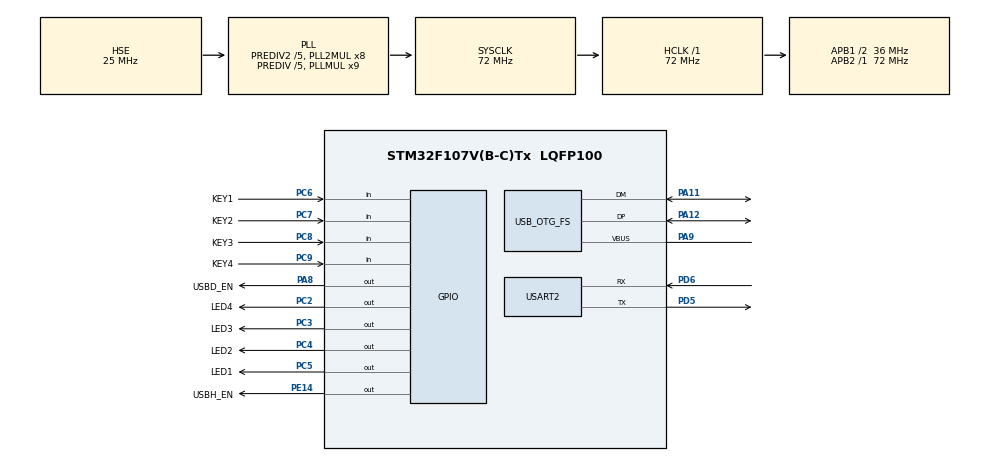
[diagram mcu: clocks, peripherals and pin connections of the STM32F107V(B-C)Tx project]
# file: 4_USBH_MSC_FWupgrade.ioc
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FATFS._MAX_LFN=100
FATFS._USE_LFN=0
Mcu.Family=STM32F1
Mcu.Name=STM32F107V(B-C)Tx
Mcu.Package=LQFP100
NVIC.OTG_FS_IRQn=true\:0\:0\:false\:false\:true\:true\:true
NVIC.PriorityGroup=NVIC_PRIORITYGROUP_4
OSC_IN.Mode=HSE-External-Oscillator
OSC_IN.Signal=RCC_OSC_IN
OSC_OUT.Mode=HSE-External-Oscillator
OSC_OUT.Signal=RCC_OSC_OUT
PA11.Mode=Host_Only
PA11.Signal=USB_OTG_FS_DM
PA12.Mode=Host_Only
PA12.Signal=USB_OTG_FS_DP
PA13.Mode=Serial_Wire
PA13.Signal=SYS_JTMS-SWDIO
PA14.Mode=Serial_Wire
PA14.Signal=SYS_JTCK-SWCLK
PA8.GPIO_Label=USBD_EN
PA8.Signal=GPIO_Output
PA9.Mode=Activate_VBUS
PA9.Signal=USB_OTG_FS_VBUS
PC14-OSC32_IN.Mode=LSE-External-Oscillator
PC14-OSC32_IN.Signal=RCC_OSC32_IN
PC15-OSC32_OUT.Mode=LSE-External-Oscillator
PC15-OSC32_OUT.Signal=RCC_OSC32_OUT
PC2.GPIO_Label=LED4
PC2.Signal=GPIO_Output
PC3.GPIO_Label=LED3
PC3.Signal=GPIO_Output
PC4.GPIO_Label=LED2
PC4.Signal=GPIO_Output
PC5.GPIO_Label=LED1
PC5.Signal=GPIO_Output
PC6.GPIO_Label=KEY1
PC6.Signal=GPIO_Input
PC7.GPIO_Label=KEY2
PC7.Signal=GPIO_Input
PC8.GPIO_Label=KEY3
PC8.Signal=GPIO_Input
PC9.GPIO_Label=KEY4
PC9.Signal=GPIO_Input
PD5.Mode=Asynchronous
PD5.Signal=USART2_TX
PD6.Mode=Asynchronous
PD6.Signal=USART2_RX
PE14.GPIO_Label=USBH_EN
PE14.Signal=GPIO_Output
ProjectManager.HeapSize=0x2000
ProjectManager.StackSize=0x1000
ProjectManager.TargetToolchain=MDK-ARM V5
RCC.AHBFreq_Value=72000000
RCC.APB1CLKDivider=RCC_HCLK_DIV2
RCC.APB1Freq_Value=36000000
RCC.APB1TimFreq_Value=72000000
RCC.APB2Freq_Value=72000000
RCC.APB2TimFreq_Value=72000000
RCC.HCLKFreq_Value=72000000
RCC.HSEDivPLL=RCC_HSE_PREDIV_DIV5
RCC.HSE_VALUE=25000000
RCC.PLLMUL=RCC_PLL_MUL9
RCC.Prediv1Source=RCC_PREDIV1_SOURCE_PLL2
RCC.Prediv2=RCC_HSE_PREDIV2_DIV5
RCC.RTCClockSelection=RCC_RTCCLKSOURCE_LSE
RCC.SYSCLKFreq_VALUE=72000000
RCC.SYSCLKSource=RCC_SYSCLKSOURCE_PLLCLK
RCC.USBFreq_Value=48000000
USART2.VirtualMode=VM_ASYNC
USB_HOST.BSP.number=1
USB_HOST.USBH_HandleTypeDef=hUsbHostFS
USB_HOST.VirtualModeFS=Msc
USB_HOST0.BSP.STBoard=false
USB_HOST0.BSP.api=Unknown
USB_HOST0.BSP.i2caddr=0
USB_HOST0.BSP.instance=PE14
USB_HOST0.BSP.ip=GPIO
USB_HOST0.BSP.mode=Output
USB_HOST0.BSP.name=Drive_VBUS_FS
USB_HOST0.BSP.solution=PE14
USB_OTG_FS.VirtualMode=Host_Only
VP_FATFS_VS_USB.Mode=USB
VP_USB_HOST_VS_USB_HOST_MSC_FS.Mode=MSC_FS
board=custom

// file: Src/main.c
/* USER CODE BEGIN Header */

//           ****************************************************
//          **   Processor      : STM32F107VCT6                   **
//         ***   Frequency      : 8MHz ExtClock 72MHZ CPU Clock   ***
//        ****   AUTHOR         : Mahdi Dadashi                   ****
//       *****   STM32CubeMX    : V5.40                           *****
//      ******   STM32CubeF1    : V1.7.0                          ******
//       *****   Compiler       : KEIL uVision V5.26              *****
//        ****   Instagram      : instagram.com/mahdidadashi65/   ****
//         ***   Telegram       : t.me/mahdidadashi65/            ***
//          **   Github         : github.com/mahdidadashi65/      **
//           ****************************************************
//.-''-._.-''-._.-''-._.-''-._.-''-._.-''-._.-''-._.-''-._.-''-._.-''-._.-''-._
//.-''-._.-''-._.-''                                 ''-._.-''-._.-''-._.-''-._
//.-''-._.-''-._.-''      www.mahdidadashi.ir        ''-._.-''-._.-''-._.-''-._
//.-''-._.-''-._.-''                                 ''-._.-''-._.-''-._.-''-._
//.-''-._.-''-._.-''-._.-''-._.-''-._.-''-._.-''-._.-''-._.-''-._.-''-._.-''-._

/* USER CODE END Header */

#include "main.h"
#include "fatfs.h"
#include "usb_host.h"

/* USER CODE BEGIN Includes */
#include "MyApp.h"
/* USER CODE END Includes */

UART_HandleTypeDef huart2;

void SystemClock_Config(void);
static void MX_GPIO_Init(void);
static void MX_USART2_UART_Init(void);
void MX_USB_HOST_Process(void);

int main(void)
{

  /* MCU Configuration--------------------------------------------------------*/

  /* Reset of all peripherals, Initializes the Flash interface and the Systick. */
  HAL_Init();

  /* Configure the system clock */
  SystemClock_Config();

  /* USER CODE BEGIN SysInit */
  MyApp_RunLastApp();
  /* USER CODE END SysInit */

  /* Initialize all configured peripherals */
  MX_GPIO_Init();
  MX_USART2_UART_Init();
  MX_FATFS_Init();
  MX_USB_HOST_Init();
  /* USER CODE BEGIN 2 */
MyApp_RunBootLoader();
  /* USER CODE END 2 */

  /* Infinite loop */
  while (1)
  {
    MX_USB_HOST_Process();

  }
}

void SystemClock_Config(void)
{
  RCC_OscInitTypeDef RCC_OscInitStruct = {0};
  RCC_ClkInitTypeDef RCC_ClkInitStruct = {0};
  RCC_PeriphCLKInitTypeDef PeriphClkInit = {0};

  /** Initializes the CPU, AHB and APB busses clocks
  */
  RCC_OscInitStruct.OscillatorType = RCC_OSCILLATORTYPE_HSE;
  RCC_OscInitStruct.HSEState = RCC_HSE_ON;
  RCC_OscInitStruct.HSEPredivValue = RCC_HSE_PREDIV_DIV5;
  RCC_OscInitStruct.HSIState = RCC_HSI_ON;
  RCC_OscInitStruct.Prediv1Source = RCC_PREDIV1_SOURCE_PLL2;
  RCC_OscInitStruct.PLL.PLLState = RCC_PLL_ON;
  RCC_OscInitStruct.PLL.PLLSource = RCC_PLLSOURCE_HSE;
  RCC_OscInitStruct.PLL.PLLMUL = RCC_PLL_MUL9;
  RCC_OscInitStruct.PLL2.PLL2State = RCC_PLL2_ON;
  RCC_OscInitStruct.PLL2.PLL2MUL = RCC_PLL2_MUL8;
  RCC_OscInitStruct.PLL2.HSEPrediv2Value = RCC_HSE_PREDIV2_DIV5;
  if (HAL_RCC_OscConfig(&RCC_OscInitStruct) != HAL_OK)
  {
    Error_Handler();
  }
  /** Initializes the CPU, AHB and APB busses clocks
  */
  RCC_ClkInitStruct.ClockType = RCC_CLOCKTYPE_HCLK|RCC_CLOCKTYPE_SYSCLK
                              |RCC_CLOCKTYPE_PCLK1|RCC_CLOCKTYPE_PCLK2;
  RCC_ClkInitStruct.SYSCLKSource = RCC_SYSCLKSOURCE_PLLCLK;
  RCC_ClkInitStruct.AHBCLKDivider = RCC_SYSCLK_DIV1;
  RCC_ClkInitStruct.APB1CLKDivider = RCC_HCLK_DIV2;
  RCC_ClkInitStruct.APB2CLKDivider = RCC_HCLK_DIV1;

  if (HAL_RCC_ClockConfig(&RCC_ClkInitStruct, FLASH_LATENCY_2) != HAL_OK)
  {
    Error_Handler();
  }
  PeriphClkInit.PeriphClockSelection = RCC_PERIPHCLK_USB;
  PeriphClkInit.UsbClockSelection = RCC_USBCLKSOURCE_PLL_DIV3;
  if (HAL_RCCEx_PeriphCLKConfig(&PeriphClkInit) != HAL_OK)
  {
    Error_Handler();
  }
  /** Configure the Systick interrupt time
  */
  __HAL_RCC_PLLI2S_ENABLE();
}

static void MX_USART2_UART_Init(void)
{

  huart2.Instance = USART2;
  huart2.Init.BaudRate = 115200;
  huart2.Init.WordLength = UART_WORDLENGTH_8B;
  huart2.Init.StopBits = UART_STOPBITS_1;
  huart2.Init.Parity = UART_PARITY_NONE;
  huart2.Init.Mode = UART_MODE_TX_RX;
  huart2.Init.HwFlowCtl = UART_HWCONTROL_NONE;
  huart2.Init.OverSampling = UART_OVERSAMPLING_16;
  if (HAL_UART_Init(&huart2) != HAL_OK)
  {
    Error_Handler();
  }

}

static void MX_GPIO_Init(void)
{
  GPIO_InitTypeDef GPIO_InitStruct = {0};

  /* GPIO Ports Clock Enable */
  __HAL_RCC_GPIOC_CLK_ENABLE();
  __HAL_RCC_GPIOE_CLK_ENABLE();
  __HAL_RCC_GPIOA_CLK_ENABLE();
  __HAL_RCC_GPIOD_CLK_ENABLE();

  /*Configure GPIO pin Output Level */
  HAL_GPIO_WritePin(GPIOC, LED4_Pin|LED3_Pin|LED2_Pin|LED1_Pin, GPIO_PIN_RESET);

  /*Configure GPIO pin Output Level */
  HAL_GPIO_WritePin(USBH_EN_GPIO_Port, USBH_EN_Pin, GPIO_PIN_RESET);

  /*Configure GPIO pin Output Level */
  HAL_GPIO_WritePin(USBD_EN_GPIO_Port, USBD_EN_Pin, GPIO_PIN_RESET);

  /*Configure GPIO pins : LED4_Pin LED3_Pin LED2_Pin LED1_Pin */
  GPIO_InitStruct.Pin = LED4_Pin|LED3_Pin|LED2_Pin|LED1_Pin;
  GPIO_InitStruct.Mode = GPIO_MODE_OUTPUT_PP;
  GPIO_InitStruct.Pull = GPIO_NOPULL;
  GPIO_InitStruct.Speed = GPIO_SPEED_FREQ_LOW;
  HAL_GPIO_Init(GPIOC, &GPIO_InitStruct);

  /*Configure GPIO pin : USBH_EN_Pin */
  GPIO_InitStruct.Pin = USBH_EN_Pin;
  GPIO_InitStruct.Mode = GPIO_MODE_OUTPUT_PP;
  GPIO_InitStruct.Pull = GPIO_NOPULL;
  GPIO_InitStruct.Speed = GPIO_SPEED_FREQ_LOW;
  HAL_GPIO_Init(USBH_EN_GPIO_Port, &GPIO_InitStruct);

  /*Configure GPIO pins : KEY1_Pin KEY2_Pin KEY3_Pin KEY4_Pin */
  GPIO_InitStruct.Pin = KEY1_Pin|KEY2_Pin|KEY3_Pin|KEY4_Pin;
  GPIO_InitStruct.Mode = GPIO_MODE_INPUT;
  GPIO_InitStruct.Pull = GPIO_NOPULL;
  HAL_GPIO_Init(GPIOC, &GPIO_InitStruct);

  /*Configure GPIO pin : USBD_EN_Pin */
  GPIO_InitStruct.Pin = USBD_EN_Pin;
  GPIO_InitStruct.Mode = GPIO_MODE_OUTPUT_PP;
  GPIO_InitStruct.Pull = GPIO_NOPULL;
  GPIO_InitStruct.Speed = GPIO_SPEED_FREQ_LOW;
  HAL_GPIO_Init(USBD_EN_GPIO_Port, &GPIO_InitStruct);

}

void Error_Handler(void)
{
}

/************************ (C) COPYRIGHT STMicroelectronics *****END OF FILE****/
